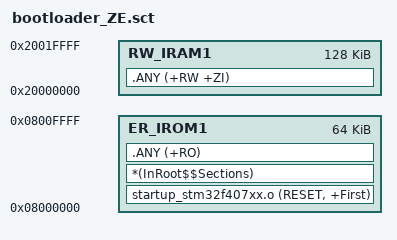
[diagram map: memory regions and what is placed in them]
; Generated STUB layout: bootloader_ZE_UNCONFIGURED
LR_IROM1 0x08000000 0x10000 {
  ER_IROM1 0x08000000 0x10000 {
    startup_stm32f407xx.o (RESET, +First)
    *(InRoot$$Sections)
    .ANY (+RO)
  }
  RW_IRAM1 0x20000000 0x20000 { .ANY (+RW +ZI) }
}
